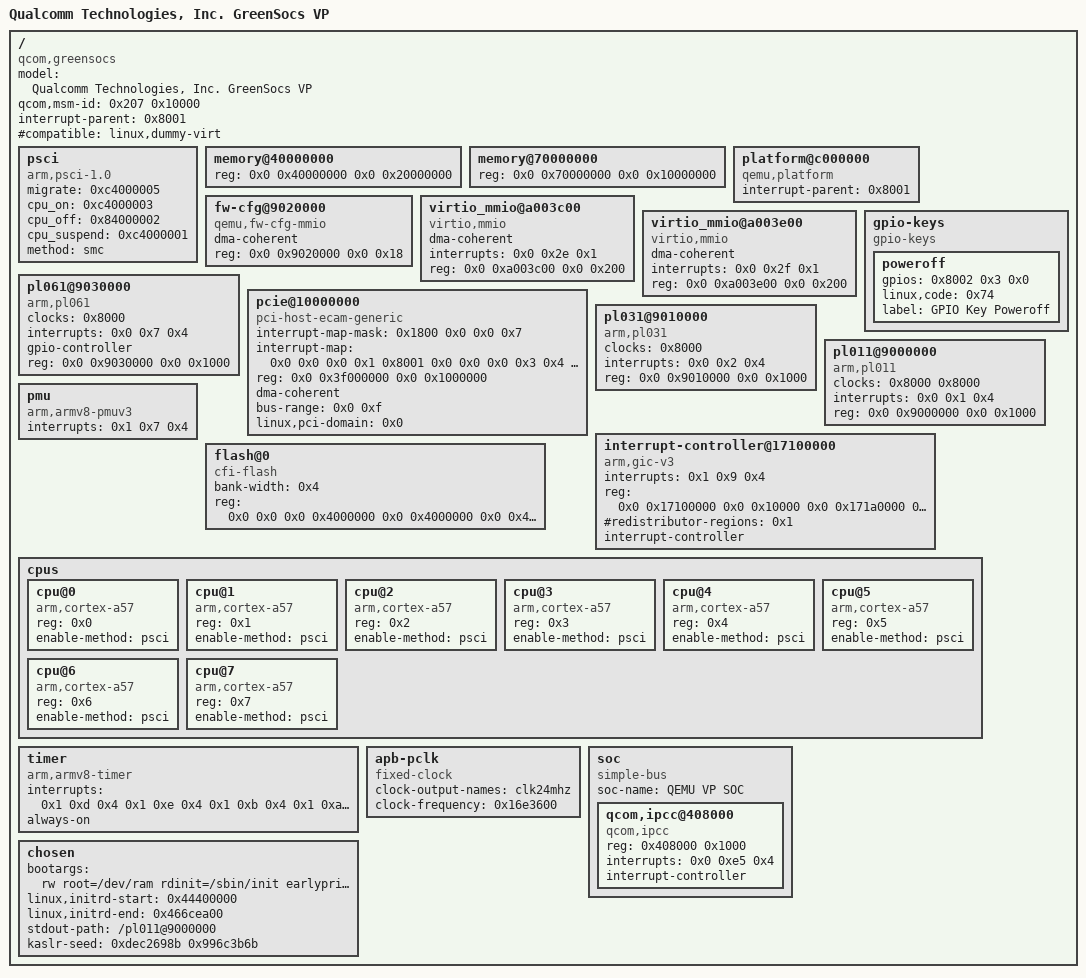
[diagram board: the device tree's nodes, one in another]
/dts-v1/;
/* Note see:
     .../msm-kernel/arch/arm64/boot/dts/vendor/qcom/kalama*.dtsi
   for the original source */

/ {
	model = "Qualcomm Technologies, Inc. GreenSocs VP";
	compatible = "qcom,greensocs";
	qcom,msm-id = <0x207 0x10000>;
	interrupt-parent = <0x8001>;
	#size-cells = <0x2>;
	#address-cells = <0x2>;
	#compatible = "linux,dummy-virt";

	psci {
		migrate = <0xc4000005>;
		cpu_on = <0xc4000003>;
		cpu_off = <0x84000002>;
		cpu_suspend = <0xc4000001>;
		method = "smc";
		compatible = "arm,psci-1.0", "arm,psci";
	};

	memory@40000000 {
		reg = <0x0 0x40000000 0x0 0x20000000>;
		device_type = "memory";
	};
	memory@70000000 {
		reg = <0x0 0x70000000 0x0 0x10000000>;
		device_type = "memory";
	};

	platform@c000000 {
		interrupt-parent = <0x8001>;
		ranges = <0x0 0x0 0xc000000 0x2000000>;
		#address-cells = <0x1>;
		#size-cells = <0x1>;
		compatible = "qemu,platform", "simple-bus";
	};

	fw-cfg@9020000 {
		dma-coherent;
		reg = <0x0 0x9020000 0x0 0x18>;
		compatible = "qemu,fw-cfg-mmio";
	};


	virtio_mmio@a003c00 {
		dma-coherent;
		interrupts = <0x0 0x2e 0x1>;
		reg = <0x0 0xa003c00 0x0 0x200>;
		compatible = "virtio,mmio";
	};

	virtio_mmio@a003e00 {
		dma-coherent;
		interrupts = <0x0 0x2f 0x1>;
		reg = <0x0 0xa003e00 0x0 0x200>;
		compatible = "virtio,mmio";
	};

	gpio-keys {
		#address-cells = <0x1>;
		#size-cells = <0x0>;
		compatible = "gpio-keys";

		poweroff {
			gpios = <0x8002 0x3 0x0>;
			linux,code = <0x74>;
			label = "GPIO Key Poweroff";
		};
	};

	pl061@9030000 {
		phandle = <0x8002>;
		clock-names = "apb_pclk";
		clocks = <0x8000>;
		interrupts = <0x0 0x7 0x4>;
		gpio-controller;
		#gpio-cells = <0x2>;
		compatible = "arm,pl061", "arm,primecell";
		reg = <0x0 0x9030000 0x0 0x1000>;
	};

	pcie@10000000 {
		interrupt-map-mask = <0x1800 0x0 0x0 0x7>;
		interrupt-map = <0x0 0x0 0x0 0x1 0x8001 0x0 0x0 0x0 0x3 0x4 0x0 0x0 0x0 0x2 0x8001 0x0 0x0 0x0 0x4 0x4 0x0 0x0 0x0 0x3 0x8001 0x0 0x0 0x0 0x5 0x4 0x0 0x0 0x0 0x4 0x8001 0x0 0x0 0x0 0x6 0x4 0x800 0x0 0x0 0x1 0x8001 0x0 0x0 0x0 0x4 0x4 0x800 0x0 0x0 0x2 0x8001 0x0 0x0 0x0 0x5 0x4 0x800 0x0 0x0 0x3 0x8001 0x0 0x0 0x0 0x6 0x4 0x800 0x0 0x0 0x4 0x8001 0x0 0x0 0x0 0x3 0x4 0x1000 0x0 0x0 0x1 0x8001 0x0 0x0 0x0 0x5 0x4 0x1000 0x0 0x0 0x2 0x8001 0x0 0x0 0x0 0x6 0x4 0x1000 0x0 0x0 0x3 0x8001 0x0 0x0 0x0 0x3 0x4 0x1000 0x0 0x0 0x4 0x8001 0x0 0x0 0x0 0x4 0x4 0x1800 0x0 0x0 0x1 0x8001 0x0 0x0 0x0 0x6 0x4 0x1800 0x0 0x0 0x2 0x8001 0x0 0x0 0x0 0x3 0x4 0x1800 0x0 0x0 0x3 0x8001 0x0 0x0 0x0 0x4 0x4 0x1800 0x0 0x0 0x4 0x8001 0x0 0x0 0x0 0x5 0x4>;
		#interrupt-cells = <0x1>;
		ranges = <0x1000000 0x0 0x0 0x0 0x3eff0000 0x0 0x10000 0x2000000 0x0 0x10000000 0x0 0x10000000 0x0 0x2eff0000>;
		reg = <0x0 0x3f000000 0x0 0x1000000>;
		dma-coherent;
		bus-range = <0x0 0xf>;
		linux,pci-domain = <0x0>;
		#size-cells = <0x2>;
		#address-cells = <0x3>;
		device_type = "pci";
		compatible = "pci-host-ecam-generic";
	};

	pl031@9010000 {
		clock-names = "apb_pclk";
		clocks = <0x8000>;
		interrupts = <0x0 0x2 0x4>;
		reg = <0x0 0x9010000 0x0 0x1000>;
		compatible = "arm,pl031", "arm,primecell";
	};

	pl011@9000000 {
		clock-names = "uartclk", "apb_pclk";
		clocks = <0x8000 0x8000>;
		interrupts = <0x0 0x1 0x4>;
		reg = <0x0 0x9000000 0x0 0x1000>;
		compatible = "arm,pl011", "arm,primecell";
	};

	pmu {
		interrupts = <0x1 0x7 0x4>;
		compatible = "arm,armv8-pmuv3";
	};

	interrupt-controller@17100000 {
		phandle = <0x8001>;
		interrupts = <0x1 0x9 0x4>;
		/* reg = <0x0 0x8000000 0x0 0x10000 0x0 0x80a0000 0x0 0xf60000>;*/
		reg = <0x0 0x17100000 0x0 0x10000 0x0 0x171a0000 0x0 0xf60000>;
		#redistributor-regions = <0x1>;
		compatible = "arm,gic-v3";
		ranges;
		#size-cells = <0x2>;
		#address-cells = <0x2>;
		interrupt-controller;
		#interrupt-cells = <0x3>;
	};

	flash@0 {
		bank-width = <0x4>;
		reg = <0x0 0x0 0x0 0x4000000 0x0 0x4000000 0x0 0x4000000>;
		compatible = "cfi-flash";
	};

	cpus {
		#size-cells = <0x0>;
		#address-cells = <0x1>;

		cpu@0 {
			reg = <0x0>;
			enable-method = "psci";
			compatible = "arm,cortex-a57";
			device_type = "cpu";
		};

		cpu@1 {
			reg = <0x1>;
			enable-method = "psci";
			compatible = "arm,cortex-a57";
			device_type = "cpu";
		};

		cpu@2 {
			reg = <0x2>;
			enable-method = "psci";
			compatible = "arm,cortex-a57";
			device_type = "cpu";
		};

		cpu@3 {
			reg = <0x3>;
			enable-method = "psci";
			compatible = "arm,cortex-a57";
			device_type = "cpu";
		};

		cpu@4 {
			reg = <0x4>;
			enable-method = "psci";
			compatible = "arm,cortex-a57";
			device_type = "cpu";
		};

		cpu@5 {
			reg = <0x5>;
			enable-method = "psci";
			compatible = "arm,cortex-a57";
			device_type = "cpu";
		};

		cpu@6 {
			reg = <0x6>;
			enable-method = "psci";
			compatible = "arm,cortex-a57";
			device_type = "cpu";
		};

		cpu@7 {
			reg = <0x7>;
			enable-method = "psci";
			compatible = "arm,cortex-a57";
			device_type = "cpu";
		};
	};

	timer {
		interrupts = <0x1 0xd 0x4 0x1 0xe 0x4 0x1 0xb 0x4 0x1 0xa 0x4>;
		always-on;
		compatible = "arm,armv8-timer", "arm,armv7-timer";
	};

	apb-pclk {
		phandle = <0x8000>;
		clock-output-names = "clk24mhz";
		clock-frequency = <0x16e3600>;
		#clock-cells = <0x0>;
		compatible = "fixed-clock";
	};

	soc {
		#address-cells = <0x1>;
		#size-cells = <0x1>;
		ranges = <0x0 0x0 0x0 0xffffffff>;
		compatible = "simple-bus";
		phandle = <0x1b3>;
		soc-name = "QEMU VP SOC";

		qcom,ipcc@408000 {
			compatible = "qcom,ipcc";
			reg = <0x408000 0x1000>;
			interrupts = <0x0 0xe5 0x4>;
			interrupt-controller;
/* XXX_SM */
			#address-cells = <0x1>;
			#interrupt-cells = <0x3>;
			#mbox-cells = <0x2>;
			phandle = <0x52>;
		};

        };

	chosen {
		bootargs = "rw root=/dev/ram rdinit=/sbin/init earlyprintk=serial,ttyAMA0 console=ttyAMA0";
		linux,initrd-start = <0x44400000>;
		linux,initrd-end = <0x466cea00>;
		stdout-path = "/pl011@9000000";
		kaslr-seed = <0xdec2698b 0x996c3b6b>;
	};


};


